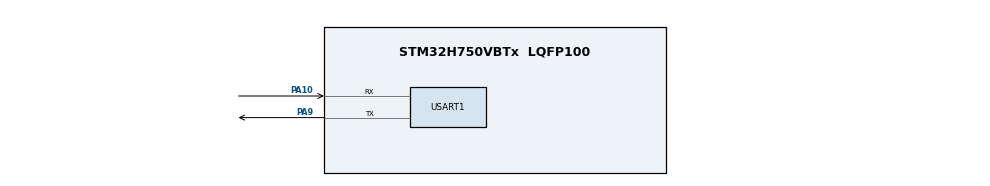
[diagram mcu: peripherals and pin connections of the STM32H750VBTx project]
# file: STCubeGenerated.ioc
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Dma.Request0=USART1_TX
Dma.USART1_TX.0.Direction=DMA_MEMORY_TO_PERIPH
Dma.USART1_TX.0.EventEnable=DISABLE
Dma.USART1_TX.0.FIFOMode=DMA_FIFOMODE_DISABLE
Dma.USART1_TX.0.Instance=DMA1_Stream1
Dma.USART1_TX.0.MemDataAlignment=DMA_MDATAALIGN_BYTE
Dma.USART1_TX.0.MemInc=DMA_MINC_ENABLE
Dma.USART1_TX.0.Mode=DMA_NORMAL
Dma.USART1_TX.0.PeriphDataAlignment=DMA_PDATAALIGN_BYTE
Dma.USART1_TX.0.PeriphInc=DMA_PINC_DISABLE
Dma.USART1_TX.0.Polarity=HAL_DMAMUX_REQ_GEN_RISING
Dma.USART1_TX.0.Priority=DMA_PRIORITY_LOW
Dma.USART1_TX.0.RequestNumber=1
Dma.USART1_TX.0.SignalID=NONE
Dma.USART1_TX.0.SyncEnable=DISABLE
Dma.USART1_TX.0.SyncPolarity=HAL_DMAMUX_SYNC_NO_EVENT
Dma.USART1_TX.0.SyncRequestNumber=1
Dma.USART1_TX.0.SyncSignalID=NONE
Mcu.Family=STM32H7
Mcu.Name=STM32H750VBTx
Mcu.Package=LQFP100
NVIC.DMA1_Stream1_IRQn=true\:0\:0\:false\:false\:true\:false\:true
NVIC.PriorityGroup=NVIC_PRIORITYGROUP_4
NVIC.USART1_IRQn=true\:0\:0\:false\:false\:true\:true\:true
PA10.Mode=Asynchronous
PA10.Signal=USART1_RX
PA13\ (JTMS/SWDIO).Mode=Serial_Wire
PA13\ (JTMS/SWDIO).Signal=DEBUG_JTMS-SWDIO
PA14\ (JTCK/SWCLK).Mode=Serial_Wire
PA14\ (JTCK/SWCLK).Signal=DEBUG_JTCK-SWCLK
PA9.Mode=Asynchronous
PA9.Signal=USART1_TX
PH0-OSC_IN\ (PH0).Mode=HSE-External-Oscillator
PH0-OSC_IN\ (PH0).Signal=RCC_OSC_IN
PH1-OSC_OUT\ (PH1).Mode=HSE-External-Oscillator
PH1-OSC_OUT\ (PH1).Signal=RCC_OSC_OUT
ProjectManager.HeapSize=0x200
ProjectManager.StackSize=0x400
ProjectManager.TargetToolchain=MDK-ARM V5
RCC.ADCFreq_Value=50390625
RCC.APB1Freq_Value=71875000
RCC.APB2Freq_Value=71875000
RCC.APB3Freq_Value=71875000
RCC.APB4Freq_Value=71875000
RCC.CortexFreq_Value=287500000
RCC.D1PPRE=RCC_APB3_DIV2
RCC.D2PPRE1=RCC_APB1_DIV2
RCC.D2PPRE2=RCC_APB2_DIV2
RCC.D3PPRE=RCC_APB4_DIV2
RCC.DIVM1=2
RCC.DIVN1=46
RCC.DIVR1=4
RCC.HCLKFreq_Value=143750000
RCC.HPRE=RCC_HCLK_DIV2
RCC.PLL2FRACN=0
RCC.PLL3FRACN=0
RCC.PLLFRACN=0
RCC.PLLSourceVirtual=RCC_PLLSOURCE_HSE
RCC.SYSCLKFreq_VALUE=287500000
RCC.SYSCLKSource=RCC_SYSCLKSOURCE_PLLCLK
RCC.USBFreq_Value=287500000
USART1.MSBFirstParam=ADVFEATURE_MSBFIRST_DISABLE
USART1.VirtualMode-Asynchronous=VM_ASYNC
board=custom

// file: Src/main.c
/* USER CODE BEGIN Header */
/**
  ******************************************************************************
  * @file           : main.c
  * @brief          : Main program body
  ******************************************************************************
  * @attention
  *
  * Copyright (c) 2021 STMicroelectronics.
  * All rights reserved.
  *
  * This software is licensed under terms that can be found in the LICENSE file
  * in the root directory of this software component.
  * If no LICENSE file comes with this software, it is provided AS-IS.
  *
  ******************************************************************************
  */
/* USER CODE END Header */
#include "main.h"

/* USER CODE BEGIN Includes */
#include "cmsis_os2.h"

/* USER CODE END Includes */

UART_HandleTypeDef huart1;
DMA_HandleTypeDef hdma_usart1_tx;

void SystemClock_Config(void);
static void MX_GPIO_Init(void);
static void MX_USART1_UART_Init(void);
static void MX_DMA_Init(void);
/* USER CODE BEGIN PFP */
extern void app_entry(void);

/* USER CODE END PFP */

/* USER CODE BEGIN 0 */
uint32_t HAL_GetTick (void) {
 static uint32_t ticks = 0U;
 uint32_t i;
 if (osKernelGetState () == osKernelRunning) {
   return ((uint32_t)osKernelGetTickCount ());
 }
 /* If Kernel is not running wait approximately 1 ms then increment and return auxiliary tick counter value */
 for (i = (SystemCoreClock >> 14U); i > 0U; i--) { __NOP(); __NOP(); __NOP(); __NOP(); __NOP(); __NOP(); __NOP(); __NOP(); __NOP(); __NOP(); __NOP(); __NOP(); }
 return ++ticks;
}

/* USER CODE END 0 */

int main(void)
{

  /* MCU Configuration--------------------------------------------------------*/

  /* Reset of all peripherals, Initializes the Flash interface and the Systick. */
  HAL_Init();

  /* Configure the system clock */
  SystemClock_Config();

  /* Initialize all configured peripherals */
  MX_GPIO_Init();
  MX_USART1_UART_Init();
  MX_DMA_Init();
  /* USER CODE BEGIN 2 */
  SystemCoreClockUpdate();
  HAL_SYSTICK_Config(SystemCoreClock / 1000);
  app_entry();
  /* USER CODE END 2 */

  /* Infinite loop */
  while (1)
  {

  }
}

void SystemClock_Config(void)
{
  RCC_OscInitTypeDef RCC_OscInitStruct = {0};
  RCC_ClkInitTypeDef RCC_ClkInitStruct = {0};

  /** Supply configuration update enable
  */
  HAL_PWREx_ConfigSupply(PWR_LDO_SUPPLY);
  /** Configure the main internal regulator output voltage
  */
  __HAL_PWR_VOLTAGESCALING_CONFIG(PWR_REGULATOR_VOLTAGE_SCALE2);

  while(!__HAL_PWR_GET_FLAG(PWR_FLAG_VOSRDY)) {}
  /** Initializes the RCC Oscillators according to the specified parameters
  * in the RCC_OscInitTypeDef structure.
  */
  RCC_OscInitStruct.OscillatorType = RCC_OSCILLATORTYPE_HSE;
  RCC_OscInitStruct.HSEState = RCC_HSE_ON;
  RCC_OscInitStruct.PLL.PLLState = RCC_PLL_ON;
  RCC_OscInitStruct.PLL.PLLSource = RCC_PLLSOURCE_HSE;
  RCC_OscInitStruct.PLL.PLLM = 2;
  RCC_OscInitStruct.PLL.PLLN = 46;
  RCC_OscInitStruct.PLL.PLLP = 2;
  RCC_OscInitStruct.PLL.PLLQ = 2;
  RCC_OscInitStruct.PLL.PLLR = 4;
  RCC_OscInitStruct.PLL.PLLRGE = RCC_PLL1VCIRANGE_3;
  RCC_OscInitStruct.PLL.PLLVCOSEL = RCC_PLL1VCOWIDE;
  RCC_OscInitStruct.PLL.PLLFRACN = 0;
  if (HAL_RCC_OscConfig(&RCC_OscInitStruct) != HAL_OK)
  {
    Error_Handler();
  }
  /** Initializes the CPU, AHB and APB buses clocks
  */
  RCC_ClkInitStruct.ClockType = RCC_CLOCKTYPE_HCLK|RCC_CLOCKTYPE_SYSCLK
                              |RCC_CLOCKTYPE_PCLK1|RCC_CLOCKTYPE_PCLK2
                              |RCC_CLOCKTYPE_D3PCLK1|RCC_CLOCKTYPE_D1PCLK1;
  RCC_ClkInitStruct.SYSCLKSource = RCC_SYSCLKSOURCE_PLLCLK;
  RCC_ClkInitStruct.SYSCLKDivider = RCC_SYSCLK_DIV1;
  RCC_ClkInitStruct.AHBCLKDivider = RCC_HCLK_DIV2;
  RCC_ClkInitStruct.APB3CLKDivider = RCC_APB3_DIV2;
  RCC_ClkInitStruct.APB1CLKDivider = RCC_APB1_DIV2;
  RCC_ClkInitStruct.APB2CLKDivider = RCC_APB2_DIV2;
  RCC_ClkInitStruct.APB4CLKDivider = RCC_APB4_DIV2;

  if (HAL_RCC_ClockConfig(&RCC_ClkInitStruct, FLASH_LATENCY_2) != HAL_OK)
  {
    Error_Handler();
  }
}

static void MX_USART1_UART_Init(void)
{

  huart1.Instance = USART1;
  huart1.Init.BaudRate = 115200;
  huart1.Init.WordLength = UART_WORDLENGTH_8B;
  huart1.Init.StopBits = UART_STOPBITS_1;
  huart1.Init.Parity = UART_PARITY_NONE;
  huart1.Init.Mode = UART_MODE_TX_RX;
  huart1.Init.HwFlowCtl = UART_HWCONTROL_NONE;
  huart1.Init.OverSampling = UART_OVERSAMPLING_16;
  huart1.Init.OneBitSampling = UART_ONE_BIT_SAMPLE_DISABLE;
  huart1.Init.ClockPrescaler = UART_PRESCALER_DIV1;
  huart1.AdvancedInit.AdvFeatureInit = UART_ADVFEATURE_NO_INIT;
  if (HAL_UART_Init(&huart1) != HAL_OK)
  {
    Error_Handler();
  }
  if (HAL_UARTEx_SetTxFifoThreshold(&huart1, UART_TXFIFO_THRESHOLD_1_8) != HAL_OK)
  {
    Error_Handler();
  }
  if (HAL_UARTEx_SetRxFifoThreshold(&huart1, UART_RXFIFO_THRESHOLD_1_8) != HAL_OK)
  {
    Error_Handler();
  }
  if (HAL_UARTEx_DisableFifoMode(&huart1) != HAL_OK)
  {
    Error_Handler();
  }

}

static void MX_DMA_Init(void)
{

  /* DMA controller clock enable */
  __HAL_RCC_DMA1_CLK_ENABLE();

  /* DMA interrupt init */
  /* DMA1_Stream1_IRQn interrupt configuration */
  HAL_NVIC_SetPriority(DMA1_Stream1_IRQn, 0, 0);
  HAL_NVIC_EnableIRQ(DMA1_Stream1_IRQn);

}

static void MX_GPIO_Init(void)
{

  /* GPIO Ports Clock Enable */
  __HAL_RCC_GPIOH_CLK_ENABLE();
  __HAL_RCC_GPIOA_CLK_ENABLE();

}

void Error_Handler(void)
{
  __disable_irq();
  while (1)
  {
  }
}
